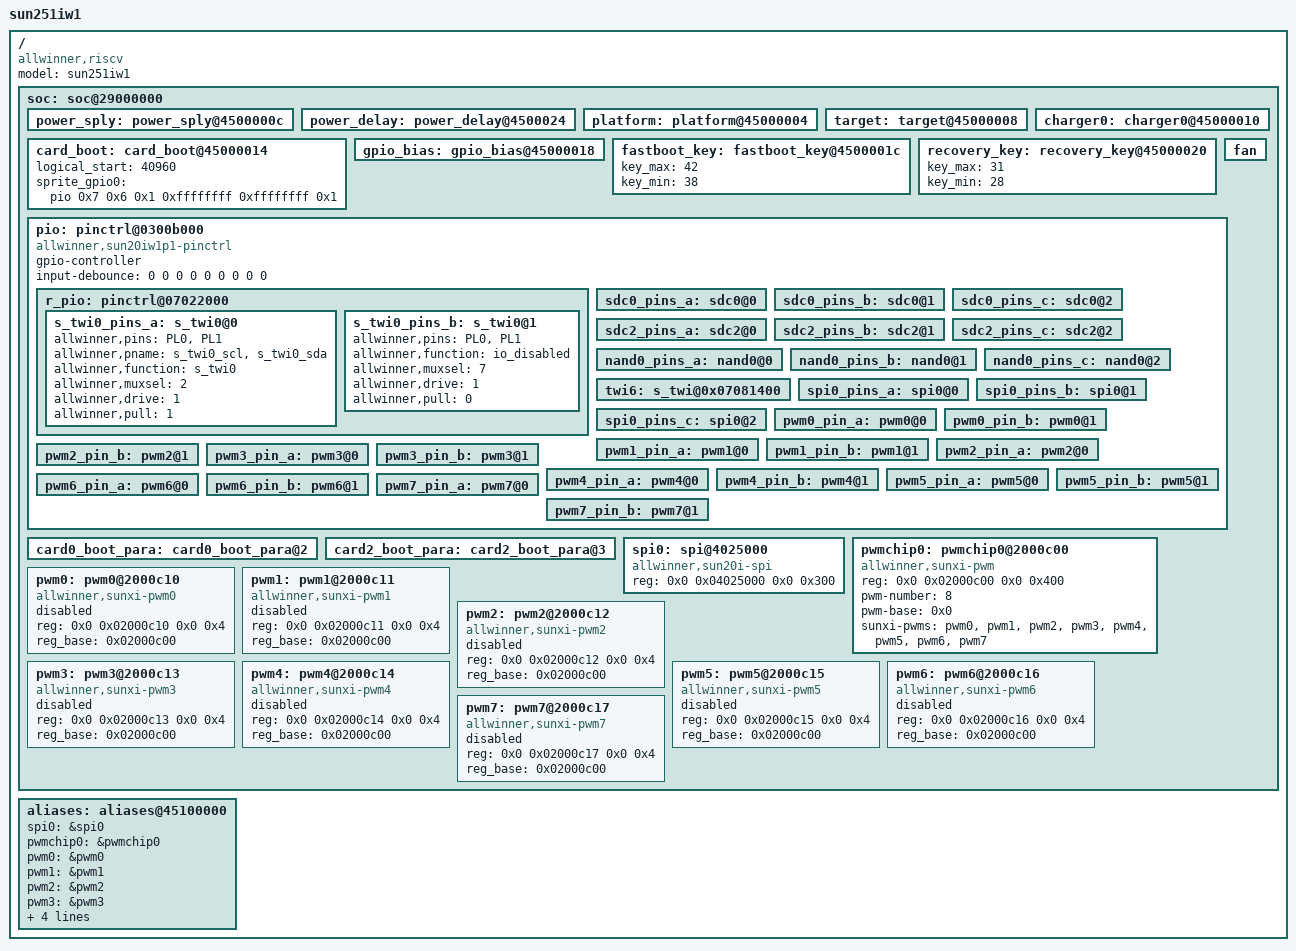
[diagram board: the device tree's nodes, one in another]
/*
 * Allwinner Technology CO., Ltd. sun20iw1p1 platform
 *
 * modify base on juno.dts
 * SPDX-License-Identifier: GPL-2.0+
 */
/dts-v1/;
#include <dt-bindings/gpio/gpio.h>
#include "sun251iw1p1-clk.dtsi"
#include <dt-bindings/thermal/thermal.h>
/ {
	model = "sun251iw1";
	compatible = "allwinner,riscv", "arm,sun251iw1p1";
	#address-cells = <2>;
	#size-cells = <2>;
	soc: soc@29000000 {
		#address-cells = <2>;
		#size-cells = <2>;
		power_sply:power_sply@4500000c {
			device_type = "power_sply";

		};

		power_delay:power_delay@4500024 {
			device_type = "power_delay";
		};

		platform:platform@45000004 {
			device_type = "platform";

		};

		target:target@45000008 {
			device_type = "target";

		};

		charger0:charger0@45000010 {
			device_type = "charger0";

		};
		card_boot:card_boot@45000014 {
			device_type = "card_boot";
			logical_start   = <40960>;
			/* sprite_gpio0 = <&pio PH 6 1 0xffffffff 0xffffffff 1>; */
			sprite_gpio0 = <&pio 0x7 0x6 0x1 0xffffffff 0xffffffff 0x1>;
		};

		gpio_bias:gpio_bias@45000018 {
			device_type = "gpio_bias";
		};

		fastboot_key:fastboot_key@4500001c {
			device_type = "fastboot_key";
			key_max = <42>;
			key_min = <38>;
		};

		recovery_key:recovery_key@45000020 {
			device_type = "recovery_key";
			key_max = <31>;
			key_min = <28>;
		};

		fan:fan {
			device_type = "fan";
		};

		pio: pinctrl@0300b000 {
			compatible = "allwinner,sun20iw1p1-pinctrl";
			device_type = "pio";
			gpio-controller;
			#size-cells = <0>;
			#gpio-cells = <6>;
			/* takes the debounce time in usec as argument */
			input-debounce = <0 0 0 0 0 0 0 0 0>;
			r_pio: pinctrl@07022000 {

				s_twi0_pins_a: s_twi0@0 {
					allwinner,pins = "PL0", "PL1";
					allwinner,pname = "s_twi0_scl", "s_twi0_sda";
					allwinner,function = "s_twi0";
					allwinner,muxsel = <2>;
					allwinner,drive = <1>;
					allwinner,pull = <1>;
				};

				s_twi0_pins_b: s_twi0@1 {
					allwinner,pins = "PL0", "PL1";
					allwinner,function = "io_disabled";
					allwinner,muxsel = <7>;
					allwinner,drive = <1>;
					allwinner,pull = <0>;
				};
			};
			sdc0_pins_a: sdc0@0 {
			};

			sdc0_pins_b: sdc0@1 {
			};

			sdc0_pins_c: sdc0@2 {
			};

			sdc2_pins_a: sdc2@0 {
			};

			sdc2_pins_b: sdc2@1 {
			};

			sdc2_pins_c: sdc2@2 {
			};

			nand0_pins_a: nand0@0 {
			};

			nand0_pins_b: nand0@1 {
			};

			nand0_pins_c: nand0@2 {
			};

			twi6: s_twi@0x07081400 {
			};

			spi0_pins_a: spi0@0 {
			};

			spi0_pins_b: spi0@1 {
			};

			spi0_pins_c: spi0@2 {
			};

			pwm0_pin_a: pwm0@0 {
			};

			pwm0_pin_b: pwm0@1 {
			};

			pwm1_pin_a: pwm1@0 {
			};

			pwm1_pin_b: pwm1@1 {
			};

			pwm2_pin_a: pwm2@0 {
			};

			pwm2_pin_b: pwm2@1 {
			};

			pwm3_pin_a: pwm3@0 {
			};

			pwm3_pin_b: pwm3@1 {
			};

			pwm4_pin_a: pwm4@0 {
			};

			pwm4_pin_b: pwm4@1 {
			};

			pwm5_pin_a: pwm5@0 {
			};

			pwm5_pin_b: pwm5@1 {
			};

			pwm6_pin_a: pwm6@0 {
			};

			pwm6_pin_b: pwm6@1 {
			};

			pwm7_pin_a: pwm7@0 {
			};

			pwm7_pin_b: pwm7@1 {
			};
		};

		card0_boot_para:card0_boot_para@2 {
			device_type = "card0_boot_para";
		};

		card2_boot_para:card2_boot_para@3 {
			device_type = "card2_boot_para";
		};

		spi0: spi@4025000 {
			#address-cells = <1>;
			#size-cells = <0>;
			compatible = "allwinner,sun20i-spi";
			device_type = "spi0";
			reg = <0x0 0x04025000 0x0 0x300>;
		};

		pwmchip0: pwmchip0@2000c00 {
			#pwm-cells = <0x3>;
			compatible = "allwinner,sunxi-pwm";
			reg = <0x0 0x02000c00 0x0 0x400>;
			pwm-number = <8>;
			pwm-base = <0x0>;
			sunxi-pwms = <&pwm0>, <&pwm1>, <&pwm2>, <&pwm3>,
				     <&pwm4>, <&pwm5>, <&pwm6>, <&pwm7>;
			status = "okay";
		};

		pwm0: pwm0@2000c10 {
			#pwm-cells = <0x3>;
			compatible = "allwinner,sunxi-pwm0";
			reg = <0x0 0x02000c10 0x0 0x4>;
			reg_base = <0x02000c00>;
			status = "disabled";
		};

		pwm1: pwm1@2000c11 {
			#pwm-cells = <0x3>;
			compatible = "allwinner,sunxi-pwm1";
			reg = <0x0 0x02000c11 0x0 0x4>;
			reg_base = <0x02000c00>;
			status = "disabled";
		};

		pwm2: pwm2@2000c12 {
			#pwm-cells = <0x3>;
			compatible = "allwinner,sunxi-pwm2";
			reg = <0x0 0x02000c12 0x0 0x4>;
			reg_base = <0x02000c00>;
			status = "disabled";
		};

		pwm3: pwm3@2000c13 {
			#pwm-cells = <0x3>;
			compatible = "allwinner,sunxi-pwm3";
			reg = <0x0 0x02000c13 0x0 0x4>;
			reg_base = <0x02000c00>;
			status = "disabled";
		};

		pwm4: pwm4@2000c14 {
			#pwm-cells = <0x3>;
			compatible = "allwinner,sunxi-pwm4";
			reg = <0x0 0x02000c14 0x0 0x4>;
			reg_base = <0x02000c00>;
			status = "disabled";
		};

		pwm5: pwm5@2000c15 {
			#pwm-cells = <0x3>;
			compatible = "allwinner,sunxi-pwm5";
			reg = <0x0 0x02000c15 0x0 0x4>;
			reg_base = <0x02000c00>;
			status = "disabled";
		};

		pwm6: pwm6@2000c16 {
			#pwm-cells = <0x3>;
			compatible = "allwinner,sunxi-pwm6";
			reg = <0x0 0x02000c16 0x0 0x4>;
			reg_base = <0x02000c00>;
			status = "disabled";
		};

		pwm7: pwm7@2000c17 {
			#pwm-cells = <0x3>;
			compatible = "allwinner,sunxi-pwm7";
			reg = <0x0 0x02000c17 0x0 0x4>;
			reg_base = <0x02000c00>;
			status = "disabled";
		};
	};

	aliases:aliases@45100000 {
		spi0 = &spi0;
		pwmchip0 = &pwmchip0;
		pwm0 = &pwm0;
		pwm1 = &pwm1;
		pwm2 = &pwm2;
		pwm3 = &pwm3;
		pwm4 = &pwm4;
		pwm5 = &pwm5;
		pwm6 = &pwm6;
		pwm7 = &pwm7;
	};

};

#include ".board-uboot.dts"
